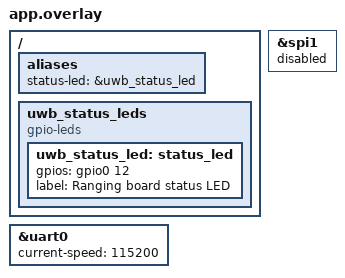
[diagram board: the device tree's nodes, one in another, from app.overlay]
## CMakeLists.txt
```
cmake_minimum_required(VERSION 3.20.0)

find_package(Zephyr REQUIRED HINTS $ENV{ZEPHYR_BASE})
project(dwm1001_tag)

# All sources are shared through Firmware/common; this directory only holds
# the node configuration (prj.conf, app.overlay, include/uwb_app_config.h).
include(${CMAKE_CURRENT_SOURCE_DIR}/../common/cmake/uwb_node.cmake)
uwb_node_setup(TAG)
```

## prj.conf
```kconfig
# DWM1001 peripheral drivers.
CONFIG_GPIO=y
CONFIG_SPI=y
CONFIG_SERIAL=y
CONFIG_UART_INTERRUPT_DRIVEN=y
CONFIG_WATCHDOG=y
CONFIG_TIMING_FUNCTIONS=y

# Ranging needs delayed TX and 40-bit timestamps, so the application uses the
# register-level DW1000 driver instead of Zephyr's generic IEEE 802.15.4 API.
CONFIG_IEEE802154=n
CONFIG_IEEE802154_DW1000=n

# UART0 belongs exclusively to telemetry.
CONFIG_CONSOLE=n
CONFIG_UART_CONSOLE=n
CONFIG_RTT_CONSOLE=n
CONFIG_LOG=n
CONFIG_BOOT_BANNER=n
CONFIG_USE_SEGGER_RTT=n

CONFIG_MAIN_STACK_SIZE=4096
CONFIG_HEAP_MEM_POOL_SIZE=0
```

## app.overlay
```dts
/ {
	aliases {
		status-led = &uwb_status_led;
	};

	uwb_status_leds {
		compatible = "gpio-leds";

		uwb_status_led: status_led {
			gpios = <&gpio0 12 GPIO_ACTIVE_HIGH>;
			label = "Ranging board status LED";
		};
	};
};

/*
 * DWM1001C module pins 26..29 are routed to the ESP32-C3 through R9..R12 on
 * the custom carrier.  They are not the internal DW1000 bus.  Keep the board
 * default SPI1 controller disabled until a dedicated nRF<->ESP protocol is
 * implemented, otherwise Zephyr can claim P0.03/P0.04/P0.06/P0.07.
 */
&spi1 {
	status = "disabled";
};

/* Module pins 20/18 map to P0.05/P0.11 and are wired to ESP RX/TX. */
&uart0 {
	current-speed = <115200>;
	status = "okay";
};
```

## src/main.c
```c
#include "dw1000_hw.h"
#include "tag_ranging.h"
#include "telemetry.h"
#include "uart_tx.h"
#include "uwb_platform.h"

#include <errno.h>
#include <zephyr/device.h>
#include <zephyr/devicetree.h>
#include <zephyr/drivers/watchdog.h>
#include <zephyr/kernel.h>

#define WATCHDOG_NODE DT_ALIAS(watchdog0)

static const struct device *const s_watchdog = DEVICE_DT_GET(WATCHDOG_NODE);
static int s_watchdog_channel = -1;

static int watchdog_start(void)
{
#if UWB_WATCHDOG_ENABLED
    const struct wdt_timeout_cfg timeout = {
        .window = {
            .min = 0U,
            .max = UWB_WATCHDOG_TIMEOUT_MS,
        },
        .callback = NULL,
        .flags = WDT_FLAG_RESET_SOC,
    };

    if (!device_is_ready(s_watchdog)) {
        return -ENODEV;
    }

    s_watchdog_channel = wdt_install_timeout(s_watchdog, &timeout);
    if (s_watchdog_channel < 0) {
        return s_watchdog_channel;
    }

    int error = wdt_setup(s_watchdog,
                          WDT_OPT_PAUSE_HALTED_BY_DBG | WDT_OPT_PAUSE_IN_SLEEP);
    if (error == -ENOTSUP) {
        error = wdt_setup(s_watchdog, 0U);
    }
    return error;
#else
    return 0;
#endif
}

static void watchdog_feed(void)
{
#if UWB_WATCHDOG_ENABLED
    if (s_watchdog_channel >= 0) {
        (void)wdt_feed(s_watchdog, s_watchdog_channel);
    }
#endif
}

static void fatal_blink(void)
{
    while (true) {
        uwb_platform_led_toggle();
        watchdog_feed();
        k_msleep(150);
    }
}

static int run_tag(void)
{
    TagCycleSnapshot_t snapshot;
    uint32_t last_stats_ms;
    uint32_t last_cycle_count;
    uint32_t last_ok_count;

    if (UART_TX_Init() != 0 || Tag_Init() != 0) {
        return -EIO;
    }

    DW1000_EnableIRQ();
    Telem_SendInfo();
    last_stats_ms = uwb_platform_time_ms();
    last_cycle_count = tag_cycle_count;
    last_ok_count = response_ok_count;
    const uint32_t spi_errors_at_start = dw1000_spi_error_count;

    while (true) {
        /* IRQ is level-held by DW1000; polling closes the edge-race window. */
        if (DW1000_IrqLineActive() != 0U) {
            dw1000_irq_flag = 1U;
        }
        Tag_Task();
        if (dw1000_spi_error_count != spi_errors_at_start) {
            /* Never publish timestamps or distances read through a failed SPI transfer. */
            return -EIO;
        }

        if (tag_cycle_ready != 0U) {
            Tag_GetSnapshot(&snapshot);
            tag_cycle_ready = 0U;
            Telem_SendRangeCycle(&snapshot);
        }

        uint32_t now = uwb_platform_time_ms();
        if ((now - last_stats_ms) >= 1000U) {
            uint32_t elapsed = now - last_stats_ms;
            uint32_t cycles = tag_cycle_count - last_cycle_count;
            uint32_t successes = response_ok_count - last_ok_count;
            uint16_t cycle_hz = (uint16_t)((cycles * 1000U) / elapsed);
            uint16_t operation_hz = (uint16_t)((successes * 1000U) / elapsed);

            Telem_SendStats(cycle_hz, operation_hz);
            Telem_SendInfo();
            last_stats_ms = now;
            last_cycle_count = tag_cycle_count;
            last_ok_count = response_ok_count;
        }

        watchdog_feed();
        k_busy_wait(10U);
    }
}

int main(void)
{
    if (uwb_platform_init() != 0) {
        fatal_blink();
    }

    MCU_TimerInit();
    if (watchdog_start() != 0) {
        fatal_blink();
    }

    if (run_tag() != 0) {
        fatal_blink();
    }

    return 0;
}
```

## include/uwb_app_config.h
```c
#ifndef UWB_APP_CONFIG_H
#define UWB_APP_CONFIG_H

#include <stdint.h>

/* Node identity. The TAG addresses anchors dynamically. */
#define TAG_ADDR ((uint16_t)0U)
#define ANCHOR_ADDR ((uint16_t)1U)

/*
 * Custom DWM1001C carrier profile.
 *
 * The large software offsets in Firmware Code Base belong to the previous
 * hardware/calibration set.  Start this PCB from the nominal DW1000 antenna
 * delay and publish measurements as calibration diagnostics until every
 * physical Tag/Anchor pair has been measured again.
 */
#define UWB_USE_DS_TWR 1
#define UWB_USE_HW_ANTENNA_DELAY 1
#define UWB_USE_LEGACY_OFFSET 0
#define UWB_USE_CLOCK_CORRECTION 0
#define UWB_DS_CALIBRATED_MASK 0U
#define UWB_DS_OFFSET_A1_M 0.0
#define UWB_DS_OFFSET_A2_M 0.0
#define UWB_DS_OFFSET_A3_M 0.0
#define UWB_DS_OFFSET_A4_M 0.0
#define UWB_DS_OFFSET_A5_M 0.0
#define UWB_DS_OFFSET_A6_M 0.0
#define UWB_DS_OFFSET_A7_M 0.0
#define UWB_DS_OFFSET_A8_M 0.0

/* Keep the former Adaptive Legacy candidate in SHADOW. The 20:55 hardware log
 * showed that its low-Q STATIC state can lag a moving range by more than
 * 200 mm on the present weak-FPP link. CAL_MISSING remains diagnostic-only;
 * choose the production firmware estimator after calibration and hardware A/B. */
#define UWB_LEGACY_ADAPTIVE_MODE 1U

/* Set to 1 for human-readable CSV, or 0 for the binary packet protocol. */
#define TELEM_ASCII 0

#define UWB_WATCHDOG_ENABLED 1
#define UWB_WATCHDOG_TIMEOUT_MS 1000U

#endif /* UWB_APP_CONFIG_H */
```
